AUTOSAR XML (schema 4-2-2)
package /Components
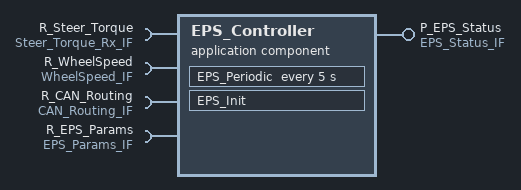
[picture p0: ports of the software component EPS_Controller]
  application sw component type EPS_Controller
    provide port P_EPS_Status: provided-interface=EPS_Status_IF
    4 x require port:
      R_Steer_Torque: required-interface=Steer_Torque_Rx_IF
      R_WheelSpeed: required-interface=WheelSpeed_IF
      R_CAN_Routing: required-interface=CAN_Routing_IF
      R_EPS_Params: required-interface=EPS_Params_IF
    behavior EPS_Controller_InternalBehavior
      init event EPS_Init_Event: start-on-event=EPS_Init
      timing event EPS_Periodic_Event: start-on-event=EPS_Periodic, period=5
      runnable EPS_Init
        data-read-access:
          access VA_Init_Read_SteerTorque: accessed-variable=R_Steer_Torque.steer_torque
        data-receive-point-by-arguments:
          access VRA_Init_SteerTorque: accessed-variable=R_Steer_Torque.steer_torque
        data-send-points:
          access VA_Init_Send_EPS_Active: accessed-variable=P_EPS_Status.eps_active
          access VA_Init_Send_EPS_FaultCode: accessed-variable=P_EPS_Status.eps_fault_code
        parameter access PA_Init_EPS_AssistGain: accessed-parameter=R_EPS_Params.eps_assist_gain
        parameter access PA_Init_EPS_Limit: accessed-parameter=R_EPS_Params.eps_limit
        sync call SCP_Init_SendEPSCommand: operation=R_CAN_Routing.SendEPSCommand, timeout=3
      runnable EPS_Periodic: minimum-start-interval=5
        data-read-access:
          4 x access:
            VA_Read_WS_FL: accessed-variable=R_WheelSpeed.wheel_speed_fl
            VA_Read_WS_FR: accessed-variable=R_WheelSpeed.wheel_speed_fr
            VA_Read_WS_RL: accessed-variable=R_WheelSpeed.wheel_speed_rl
            VA_Read_WS_RR: accessed-variable=R_WheelSpeed.wheel_speed_rr
        data-receive-point-by-arguments:
          access VRA_Read_SteerTorque: accessed-variable=R_Steer_Torque.steer_torque
        data-send-points:
          access VA_Send_EPS_Active: accessed-variable=P_EPS_Status.eps_active
          access VA_Send_EPS_FaultCode: accessed-variable=P_EPS_Status.eps_fault_code
        parameter access PA_Periodic_EPS_AssistGain: accessed-parameter=R_EPS_Params.eps_assist_gain
        sync call SCP_Periodic_SendEPSCommand: operation=R_CAN_Routing.SendEPSCommand, timeout=3
